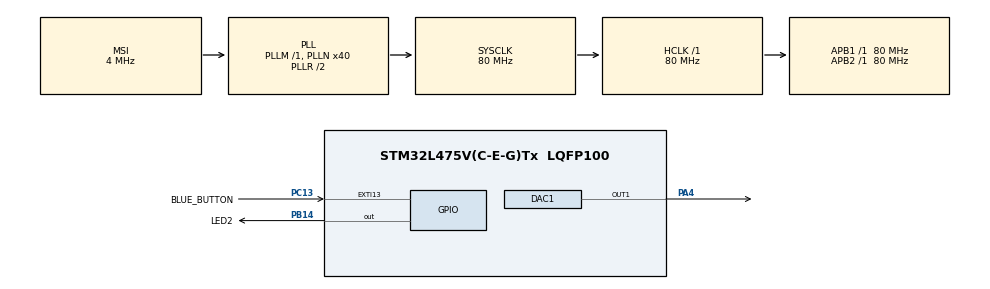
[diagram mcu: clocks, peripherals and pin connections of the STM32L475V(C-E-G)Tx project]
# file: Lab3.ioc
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DAC1.DAC_SampleAndHold-DAC_OUT1=DAC_SAMPLEANDHOLD_DISABLE
Mcu.Family=STM32L4
Mcu.Name=STM32L475V(C-E-G)Tx
Mcu.Package=LQFP100
NVIC.EXTI15_10_IRQn=true\:0\:0\:false\:false\:true\:true\:true\:true
NVIC.PriorityGroup=NVIC_PRIORITYGROUP_4
NVIC.TIM2_IRQn=true\:0\:0\:false\:false\:true\:true\:true\:true
PA4.Signal=COMP_DAC11_group
PB14.GPIO_Label=LED2
PB14.Signal=GPIO_Output
PB3\ (JTDO-TRACESWO).Signal=SYS_JTDO-SWO
PC13.GPIO_Label=BLUE_BUTTON
PC13.Signal=GPXTI13
ProjectManager.HeapSize=0x200
ProjectManager.StackSize=0x400
ProjectManager.TargetToolchain=STM32CubeIDE
RCC.ADCFreq_Value=48000000
RCC.AHBFreq_Value=80000000
RCC.APB1Freq_Value=80000000
RCC.APB1TimFreq_Value=80000000
RCC.APB2Freq_Value=80000000
RCC.APB2TimFreq_Value=80000000
RCC.CortexFreq_Value=80000000
RCC.HCLKFreq_Value=80000000
RCC.HSE_VALUE=8000000
RCC.HSI_VALUE=16000000
RCC.LSE_VALUE=32768
RCC.MSI_VALUE=4000000
RCC.PLLN=40
RCC.PLLSAI1N=24
RCC.SYSCLKFreq_VALUE=80000000
RCC.SYSCLKSource=RCC_SYSCLKSOURCE_PLLCLK
RCC.USBFreq_Value=48000000
RCC.VCOOutputFreq_Value=160000000
SH.COMP_DAC11_group.0=DAC1_OUT1,DAC_OUT1
TIM2.Period=1815
TIM2.TIM_MasterOutputTrigger=TIM_TRGO_UPDATE
VP_TIM2_VS_ClockSourceINT.Mode=Internal
board=B-L475E-IOT01A2

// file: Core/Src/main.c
/* USER CODE BEGIN Header */
/**
 ******************************************************************************
 * @file           : main.c
 * @brief          : Main program body
 ******************************************************************************
 * @attention
 *
 * Copyright (c) 2023 STMicroelectronics.
 * All rights reserved.
 *
 * This software is licensed under terms that can be found in the LICENSE file
 * in the root directory of this software component.
 * If no LICENSE file comes with this software, it is provided AS-IS.
 *
 ******************************************************************************
 */
/* USER CODE END Header */
#include "main.h"

DAC_HandleTypeDef hdac1;

TIM_HandleTypeDef htim2;

/* USER CODE BEGIN PV */
int led2_on = 0;
/* USER CODE END PV */

void SystemClock_Config(void);
static void MX_GPIO_Init(void);
static void MX_TIM2_Init(void);
static void MX_DAC1_Init(void);

/* USER CODE BEGIN 0 */
void HAL_GPIO_EXTI_Callback(uint16_t GPIO_Pin) {
	switch (GPIO_Pin) {
	case BLUE_BUTTON_Pin: {
		led2_on = !led2_on;
		break;
	}
	}
	return;
}
/* USER CODE END 0 */

int main(void)
{

	/* MCU Configuration--------------------------------------------------------*/

	/* Reset of all peripherals, Initializes the Flash interface and the Systick. */
	HAL_Init();

	/* Configure the system clock */
	SystemClock_Config();

	/* Initialize all configured peripherals */
	MX_GPIO_Init();
	MX_TIM2_Init();
	MX_DAC1_Init();

	/* Infinite loop */
	while (1)
	{
		if (led2_on) {
			HAL_GPIO_TogglePin(LED2_GPIO_Port, LED2_Pin);
		}
	}
}

void SystemClock_Config(void)
{
	RCC_OscInitTypeDef RCC_OscInitStruct = {0};
	RCC_ClkInitTypeDef RCC_ClkInitStruct = {0};

	/** Configure the main internal regulator output voltage
	 */
	if (HAL_PWREx_ControlVoltageScaling(PWR_REGULATOR_VOLTAGE_SCALE1) != HAL_OK)
	{
		Error_Handler();
	}

	/** Initializes the RCC Oscillators according to the specified parameters
	 * in the RCC_OscInitTypeDef structure.
	 */
	RCC_OscInitStruct.OscillatorType = RCC_OSCILLATORTYPE_MSI;
	RCC_OscInitStruct.MSIState = RCC_MSI_ON;
	RCC_OscInitStruct.MSICalibrationValue = 0;
	RCC_OscInitStruct.MSIClockRange = RCC_MSIRANGE_6;
	RCC_OscInitStruct.PLL.PLLState = RCC_PLL_ON;
	RCC_OscInitStruct.PLL.PLLSource = RCC_PLLSOURCE_MSI;
	RCC_OscInitStruct.PLL.PLLM = 1;
	RCC_OscInitStruct.PLL.PLLN = 40;
	RCC_OscInitStruct.PLL.PLLP = RCC_PLLP_DIV7;
	RCC_OscInitStruct.PLL.PLLQ = RCC_PLLQ_DIV2;
	RCC_OscInitStruct.PLL.PLLR = RCC_PLLR_DIV2;
	if (HAL_RCC_OscConfig(&RCC_OscInitStruct) != HAL_OK)
	{
		Error_Handler();
	}

	/** Initializes the CPU, AHB and APB buses clocks
	 */
	RCC_ClkInitStruct.ClockType = RCC_CLOCKTYPE_HCLK|RCC_CLOCKTYPE_SYSCLK
			|RCC_CLOCKTYPE_PCLK1|RCC_CLOCKTYPE_PCLK2;
	RCC_ClkInitStruct.SYSCLKSource = RCC_SYSCLKSOURCE_PLLCLK;
	RCC_ClkInitStruct.AHBCLKDivider = RCC_SYSCLK_DIV1;
	RCC_ClkInitStruct.APB1CLKDivider = RCC_HCLK_DIV1;
	RCC_ClkInitStruct.APB2CLKDivider = RCC_HCLK_DIV1;

	if (HAL_RCC_ClockConfig(&RCC_ClkInitStruct, FLASH_LATENCY_4) != HAL_OK)
	{
		Error_Handler();
	}
}

static void MX_DAC1_Init(void)
{

	DAC_ChannelConfTypeDef sConfig = {0};

	/** DAC Initialization
	 */
	hdac1.Instance = DAC1;
	if (HAL_DAC_Init(&hdac1) != HAL_OK)
	{
		Error_Handler();
	}

	/** DAC channel OUT1 config
	 */
	sConfig.DAC_SampleAndHold = DAC_SAMPLEANDHOLD_DISABLE;
	sConfig.DAC_Trigger = DAC_TRIGGER_NONE;
	sConfig.DAC_OutputBuffer = DAC_OUTPUTBUFFER_ENABLE;
	sConfig.DAC_ConnectOnChipPeripheral = DAC_CHIPCONNECT_DISABLE;
	sConfig.DAC_UserTrimming = DAC_TRIMMING_FACTORY;
	if (HAL_DAC_ConfigChannel(&hdac1, &sConfig, DAC_CHANNEL_1) != HAL_OK)
	{
		Error_Handler();
	}

}

static void MX_TIM2_Init(void)
{

	TIM_ClockConfigTypeDef sClockSourceConfig = {0};
	TIM_MasterConfigTypeDef sMasterConfig = {0};

	htim2.Instance = TIM2;
	htim2.Init.Prescaler = 0;
	htim2.Init.CounterMode = TIM_COUNTERMODE_UP;
	htim2.Init.Period = 1815;
	htim2.Init.ClockDivision = TIM_CLOCKDIVISION_DIV1;
	htim2.Init.AutoReloadPreload = TIM_AUTORELOAD_PRELOAD_DISABLE;
	if (HAL_TIM_Base_Init(&htim2) != HAL_OK)
	{
		Error_Handler();
	}
	sClockSourceConfig.ClockSource = TIM_CLOCKSOURCE_INTERNAL;
	if (HAL_TIM_ConfigClockSource(&htim2, &sClockSourceConfig) != HAL_OK)
	{
		Error_Handler();
	}
	sMasterConfig.MasterOutputTrigger = TIM_TRGO_UPDATE;
	sMasterConfig.MasterSlaveMode = TIM_MASTERSLAVEMODE_DISABLE;
	if (HAL_TIMEx_MasterConfigSynchronization(&htim2, &sMasterConfig) != HAL_OK)
	{
		Error_Handler();
	}

}

static void MX_GPIO_Init(void)
{
	GPIO_InitTypeDef GPIO_InitStruct = {0};

	/* GPIO Ports Clock Enable */
	__HAL_RCC_GPIOC_CLK_ENABLE();
	__HAL_RCC_GPIOA_CLK_ENABLE();
	__HAL_RCC_GPIOB_CLK_ENABLE();

	/*Configure GPIO pin Output Level */
	HAL_GPIO_WritePin(LED2_GPIO_Port, LED2_Pin, GPIO_PIN_RESET);

	/*Configure GPIO pin : BLUE_BUTTON_Pin */
	GPIO_InitStruct.Pin = BLUE_BUTTON_Pin;
	GPIO_InitStruct.Mode = GPIO_MODE_IT_RISING;
	GPIO_InitStruct.Pull = GPIO_NOPULL;
	HAL_GPIO_Init(BLUE_BUTTON_GPIO_Port, &GPIO_InitStruct);

	/*Configure GPIO pin : LED2_Pin */
	GPIO_InitStruct.Pin = LED2_Pin;
	GPIO_InitStruct.Mode = GPIO_MODE_OUTPUT_PP;
	GPIO_InitStruct.Pull = GPIO_NOPULL;
	GPIO_InitStruct.Speed = GPIO_SPEED_FREQ_LOW;
	HAL_GPIO_Init(LED2_GPIO_Port, &GPIO_InitStruct);

	/* EXTI interrupt init*/
	HAL_NVIC_SetPriority(EXTI15_10_IRQn, 0, 0);
	HAL_NVIC_EnableIRQ(EXTI15_10_IRQn);

}

void Error_Handler(void)
{
	__disable_irq();
	while (1)
	{
	}
}
